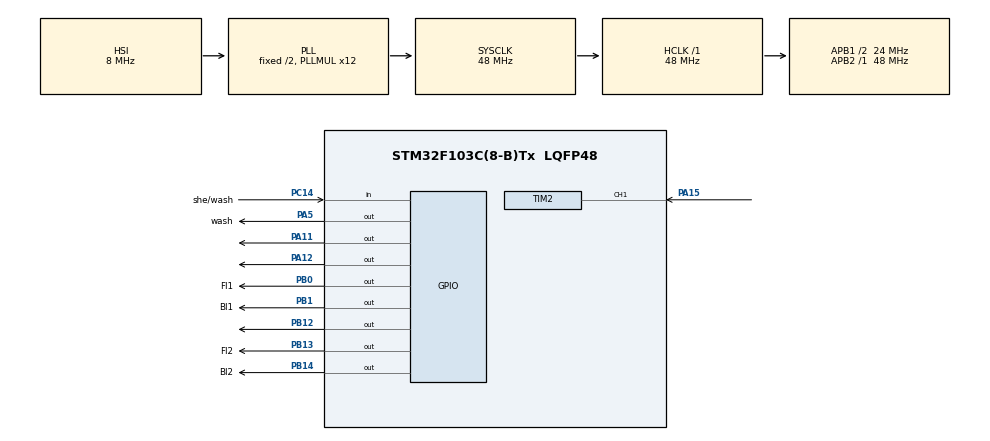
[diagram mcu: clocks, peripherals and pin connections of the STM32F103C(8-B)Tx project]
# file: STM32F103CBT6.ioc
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Mcu.Family=STM32F1
Mcu.Name=STM32F103C(8-B)Tx
Mcu.Package=LQFP48
NVIC.PriorityGroup=NVIC_PRIORITYGROUP_4
NVIC.TIM2_IRQn=true\:0\:0\:false\:false\:true\:true\:true\:true
PA11.Signal=GPIO_Output
PA12.Signal=GPIO_Output
PA13.Mode=Serial_Wire
PA13.Signal=SYS_JTMS-SWDIO
PA14.Mode=Serial_Wire
PA14.Signal=SYS_JTCK-SWCLK
PA15.Signal=S_TIM2_CH1_ETR
PA5.GPIO_Label=wash
PA5.Signal=GPIO_Output
PB0.GPIO_Label=FI1
PB0.Signal=GPIO_Output
PB1.GPIO_Label=BI1
PB1.Signal=GPIO_Output
PB12.Signal=GPIO_Output
PB13.GPIO_Label=FI2
PB13.Signal=GPIO_Output
PB14.GPIO_Label=BI2
PB14.Signal=GPIO_Output
PC14-OSC32_IN.GPIO_Label=she/wash
PC14-OSC32_IN.GPIO_PuPd=GPIO_PULLUP
PC14-OSC32_IN.Signal=GPIO_Input
ProjectManager.HeapSize=0x200
ProjectManager.StackSize=0x400
ProjectManager.TargetToolchain=MDK-ARM V5.32
RCC.AHBFreq_Value=48000000
RCC.APB1CLKDivider=RCC_HCLK_DIV2
RCC.APB1Freq_Value=24000000
RCC.APB1TimFreq_Value=48000000
RCC.APB2Freq_Value=48000000
RCC.APB2TimFreq_Value=48000000
RCC.HCLKFreq_Value=48000000
RCC.PLLMUL=RCC_PLL_MUL12
RCC.SYSCLKFreq_VALUE=48000000
RCC.SYSCLKSource=RCC_SYSCLKSOURCE_PLLCLK
RCC.USBFreq_Value=48000000
SH.S_TIM2_CH1_ETR.0=TIM2_CH1,Input_Capture1_from_TI1
TIM2.AutoReloadPreload=TIM_AUTORELOAD_PRELOAD_ENABLE
TIM2.Channel-Input_Capture1_from_TI1=TIM_CHANNEL_1
TIM2.Prescaler=24-1
VP_TIM2_VS_ClockSourceINT.Mode=Internal
board=custom

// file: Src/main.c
/* USER CODE BEGIN Header */
/**
  ******************************************************************************
  * @file           : main.c
  * @brief          : Main program body
  ******************************************************************************
  * @attention
  *
  * Copyright (c) 2024 STMicroelectronics.
  * All rights reserved.
  *
  * This software is licensed under terms that can be found in the LICENSE file
  * in the root directory of this software component.
  * If no LICENSE file comes with this software, it is provided AS-IS.
  *
  ******************************************************************************
  */
/* USER CODE END Header */
#include "main.h"
#include "tim.h"
#include "gpio.h"

/* USER CODE BEGIN Includes */
#include "motor.h"
/* USER CODE END Includes */

void SystemClock_Config(void);

/* USER CODE BEGIN 0 */
int count = 0;

void ctrl_wash()	// 控制洗牌电机
{
	WASH_CTRL(1);

	HAL_GPIO_WritePin(WASH_MOTOR_GPIO_PROT,WASH_MOTOR_GPIO_PIN,GPIO_PIN_SET);
}

/* USER CODE END 0 */

int main(void)
{

  /* MCU Configuration--------------------------------------------------------*/

  /* Reset of all peripherals, Initializes the Flash interface and the Systick. */
  HAL_Init();

  /* Configure the system clock */
  SystemClock_Config();

  /* Initialize all configured peripherals */
  MX_GPIO_Init();
  MX_TIM2_Init();

  /* Infinite loop */
  while (1)
  {

    /* USER CODE BEGIN 3 */
	  ctrl_wash();

	// 洗牌电机驱动

	//WASH_MOTOR_CTRL(1);

	 /* 按键控制洗牌开关 */
	 /*if(HAL_GPIO_ReadPin(GPIOC,GPIO_PIN_14)==0)
	 {
		  HAL_GPIO_TogglePin(WASH_MOTOR_GPIO_PROT,WASH_MOTOR_GPIO_PIN);

   		  HAL_GPIO_WritePin(GPIOB,GPIO_PIN_0,GPIO_PIN_SET);
		  HAL_GPIO_WritePin(GPIOB,GPIO_PIN_1,GPIO_PIN_RESET);

		 while(HAL_GPIO_ReadPin(GPIOC,GPIO_PIN_14)==0);
	  }*/

    //HAL_GPIO_WritePin(GPIOB,GPIO_PIN_13,GPIO_PIN_SET);
	//HAL_GPIO_WritePin(GPIOB,GPIO_PIN_14,GPIO_PIN_RESET);*/
	/*
	// 腰盘电机驱动
	HAL_GPIO_WritePin(GPIOB,GPIO_PIN_0,GPIO_PIN_SET);
	HAL_GPIO_WritePin(GPIOB,GPIO_PIN_1,GPIO_PIN_RESET);

	// 发牌电机驱动
	HAL_GPIO_WritePin(GPIOB,GPIO_PIN_13,GPIO_PIN_SET);
	HAL_GPIO_WritePin(GPIOB,GPIO_PIN_14,GPIO_PIN_RESET);
	  */

  }
  /* USER CODE END 3 */
}

void SystemClock_Config(void)
{
  RCC_OscInitTypeDef RCC_OscInitStruct = {0};
  RCC_ClkInitTypeDef RCC_ClkInitStruct = {0};

  /** Initializes the RCC Oscillators according to the specified parameters
  * in the RCC_OscInitTypeDef structure.
  */
  RCC_OscInitStruct.OscillatorType = RCC_OSCILLATORTYPE_HSI;
  RCC_OscInitStruct.HSIState = RCC_HSI_ON;
  RCC_OscInitStruct.HSICalibrationValue = RCC_HSICALIBRATION_DEFAULT;
  RCC_OscInitStruct.PLL.PLLState = RCC_PLL_ON;
  RCC_OscInitStruct.PLL.PLLSource = RCC_PLLSOURCE_HSI_DIV2;
  RCC_OscInitStruct.PLL.PLLMUL = RCC_PLL_MUL12;
  if (HAL_RCC_OscConfig(&RCC_OscInitStruct) != HAL_OK)
  {
    Error_Handler();
  }

  /** Initializes the CPU, AHB and APB buses clocks
  */
  RCC_ClkInitStruct.ClockType = RCC_CLOCKTYPE_HCLK|RCC_CLOCKTYPE_SYSCLK
                              |RCC_CLOCKTYPE_PCLK1|RCC_CLOCKTYPE_PCLK2;
  RCC_ClkInitStruct.SYSCLKSource = RCC_SYSCLKSOURCE_PLLCLK;
  RCC_ClkInitStruct.AHBCLKDivider = RCC_SYSCLK_DIV1;
  RCC_ClkInitStruct.APB1CLKDivider = RCC_HCLK_DIV2;
  RCC_ClkInitStruct.APB2CLKDivider = RCC_HCLK_DIV1;

  if (HAL_RCC_ClockConfig(&RCC_ClkInitStruct, FLASH_LATENCY_1) != HAL_OK)
  {
    Error_Handler();
  }
}

void Error_Handler(void)
{
  __disable_irq();
  while (1)
  {
  }
}
